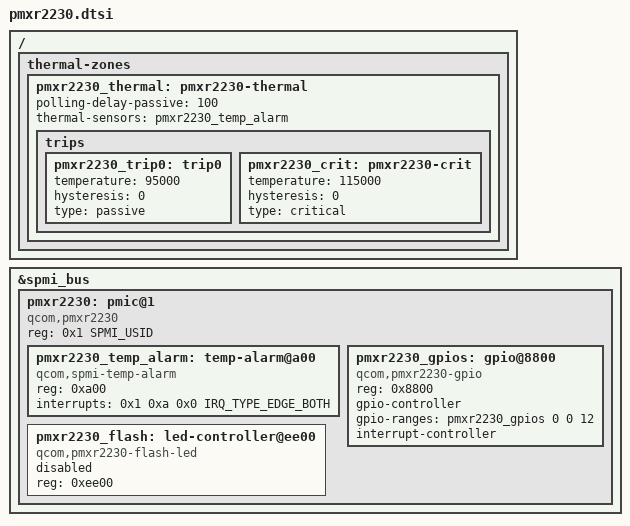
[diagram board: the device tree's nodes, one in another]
// SPDX-License-Identifier: BSD-3-Clause
/*
 * Copyright (c) 2025, Luca Weiss <luca.weiss@fairphone.com>
 */

#include <dt-bindings/interrupt-controller/irq.h>
#include <dt-bindings/spmi/spmi.h>

/ {
	thermal-zones {
		pmxr2230_thermal: pmxr2230-thermal {
			polling-delay-passive = <100>;

			thermal-sensors = <&pmxr2230_temp_alarm>;

			trips {
				pmxr2230_trip0: trip0 {
					temperature = <95000>;
					hysteresis = <0>;
					type = "passive";
				};

				pmxr2230_crit: pmxr2230-crit {
					temperature = <115000>;
					hysteresis = <0>;
					type = "critical";
				};
			};
		};
	};
};

&spmi_bus {
	pmxr2230: pmic@1 {
		compatible = "qcom,pmxr2230", "qcom,spmi-pmic";
		reg = <0x1 SPMI_USID>;
		#address-cells = <1>;
		#size-cells = <0>;

		pmxr2230_temp_alarm: temp-alarm@a00 {
			compatible = "qcom,spmi-temp-alarm";
			reg = <0xa00>;
			interrupts = <0x1 0xa 0x0 IRQ_TYPE_EDGE_BOTH>;
			#thermal-sensor-cells = <0>;
		};

		pmxr2230_gpios: gpio@8800 {
			compatible = "qcom,pmxr2230-gpio", "qcom,spmi-gpio";
			reg = <0x8800>;
			gpio-controller;
			gpio-ranges = <&pmxr2230_gpios 0 0 12>;
			#gpio-cells = <2>;
			interrupt-controller;
			#interrupt-cells = <2>;
		};

		pmxr2230_flash: led-controller@ee00 {
			compatible = "qcom,pmxr2230-flash-led", "qcom,spmi-flash-led";
			reg = <0xee00>;
			status = "disabled";
		};
	};
};
